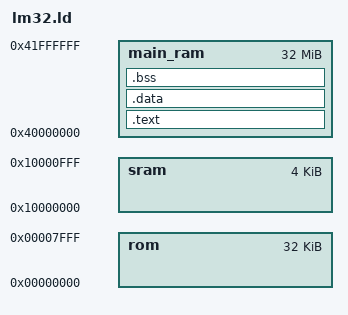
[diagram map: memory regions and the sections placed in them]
/****************************************************************************
 * boards/misoc/lm32/misoc/scripts/lm32.ld
 *
 * Licensed to the Apache Software Foundation (ASF) under one or more
 * contributor license agreements.  See the NOTICE file distributed with
 * this work for additional information regarding copyright ownership.  The
 * ASF licenses this file to you under the Apache License, Version 2.0 (the
 * "License"); you may not use this file except in compliance with the
 * License.  You may obtain a copy of the License at
 *
 *   http://www.apache.org/licenses/LICENSE-2.0
 *
 * Unless required by applicable law or agreed to in writing, software
 * distributed under the License is distributed on an "AS IS" BASIS, WITHOUT
 * WARRANTIES OR CONDITIONS OF ANY KIND, either express or implied.  See the
 * License for the specific language governing permissions and limitations
 * under the License.
 *
 ****************************************************************************/

ENTRY(_stext)

MEMORY
{
  rom : ORIGIN = 0x00000000, LENGTH = 0x00008000
  sram : ORIGIN = 0x10000000, LENGTH = 0x00001000
  main_ram : ORIGIN = 0x40000000, LENGTH = 0x02000000
}

SECTIONS
{
    .text : {
        _stext = ABSOLUTE(.);
        *(.vectors)
        *(.text .text.*)
        *(.fixup)
        *(.gnu.warning)
        *(.rodata .rodata.*)
        *(.gnu.linkonce.t.*)
        *(.glue_7)
        *(.glue_7t)
        *(.got)
        *(.gcc_except_table)
        *(.gnu.linkonce.r.*)
        _etext = ABSOLUTE(.);
    } > main_ram

    _eronly = ABSOLUTE(.);      /* See below                    */

    .data : {
        _sdata = ABSOLUTE(.);
        *(.data .data.*)
        *(.gnu.linkonce.d.*)
        CONSTRUCTORS
        . = ALIGN(4);
        _edata = ABSOLUTE(.);
    } > main_ram

    .bss : {            /* BSS              */
        _sbss = ABSOLUTE(.);
        *(.bss .bss.*)
        *(.gnu.linkonce.b.*)
        *(COMMON)
        . = ALIGN(4);
        _ebss = ABSOLUTE(.);
    } > main_ram
    /* Stabs debugging sections.    */
    .stab 0 : { *(.stab) }
    .stabstr 0 : { *(.stabstr) }
    .stab.excl 0 : { *(.stab.excl) }
    .stab.exclstr 0 : { *(.stab.exclstr) }
    .stab.index 0 : { *(.stab.index) }
    .stab.indexstr 0 : { *(.stab.indexstr) }
    .comment 0 : { *(.comment) }
    .debug_abbrev 0 : { *(.debug_abbrev) }
    .debug_info 0 : { *(.debug_info) }
    .debug_line 0 : { *(.debug_line) }
    .debug_pubnames 0 : { *(.debug_pubnames) }
    .debug_aranges 0 : { *(.debug_aranges) }
}

PROVIDE(_fstack = ORIGIN(main_ram) + LENGTH(main_ram) - 4);
